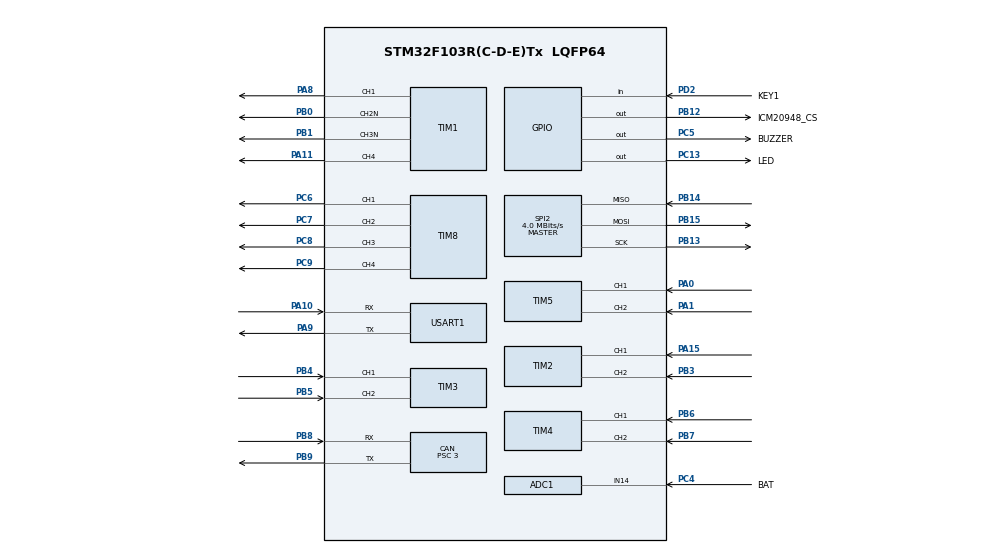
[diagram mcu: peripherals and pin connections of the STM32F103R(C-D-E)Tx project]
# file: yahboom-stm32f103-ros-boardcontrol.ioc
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ADC1.Channel-12\#ChannelRegularConversion=ADC_CHANNEL_14
ADC1.NbrOfConversionFlag=1
ADC1.Rank-12\#ChannelRegularConversion=1
ADC1.SamplingTime-12\#ChannelRegularConversion=ADC_SAMPLETIME_1CYCLE_5
ADC1.master=1
CAN.BS1=CAN_BS1_1TQ
CAN.BS2=CAN_BS2_1TQ
CAN.CalculateBaudRate=888888
CAN.CalculateTimeBit=1125
CAN.CalculateTimeQuantum=375.0
CAN.Prescaler=3
Dma.Request0=USART1_RX
Dma.Request1=USART1_TX
Dma.USART1_RX.0.Direction=DMA_PERIPH_TO_MEMORY
Dma.USART1_RX.0.Instance=DMA1_Channel5
Dma.USART1_RX.0.MemDataAlignment=DMA_MDATAALIGN_BYTE
Dma.USART1_RX.0.MemInc=DMA_MINC_ENABLE
Dma.USART1_RX.0.Mode=DMA_NORMAL
Dma.USART1_RX.0.PeriphDataAlignment=DMA_PDATAALIGN_BYTE
Dma.USART1_RX.0.PeriphInc=DMA_PINC_DISABLE
Dma.USART1_RX.0.Priority=DMA_PRIORITY_VERY_HIGH
Dma.USART1_TX.1.Direction=DMA_MEMORY_TO_PERIPH
Dma.USART1_TX.1.Instance=DMA1_Channel4
Dma.USART1_TX.1.MemDataAlignment=DMA_MDATAALIGN_BYTE
Dma.USART1_TX.1.MemInc=DMA_MINC_ENABLE
Dma.USART1_TX.1.Mode=DMA_NORMAL
Dma.USART1_TX.1.PeriphDataAlignment=DMA_PDATAALIGN_BYTE
Dma.USART1_TX.1.PeriphInc=DMA_PINC_DISABLE
Dma.USART1_TX.1.Priority=DMA_PRIORITY_VERY_HIGH
FREERTOS.Tasks01=AppController,40,128,AppControllerTask,As weak,NULL,Dynamic,NULL,NULL;AppEncoder,16,512,AppEncoderTask,As weak,NULL,Dynamic,NULL,NULL;AppIMU,24,512,AppIMUTask,As weak,NULL,Dynamic,NULL,NULL;AppManager,16,1048,AppManagerTask,As weak,NULL,Dynamic,NULL,NULL;AppHearthbeat,8,128,AppHearthbeatTask,As weak,NULL,Dynamic,NULL,NULL;AppMotion,16,512,AppMotionTask,As weak,NULL,Dynamic,NULL,NULL
FREERTOS.configTOTAL_HEAP_SIZE=16000
IWDG.Prescaler=IWDG_PRESCALER_64
Mcu.Family=STM32F1
Mcu.Name=STM32F103R(C-D-E)Tx
Mcu.Package=LQFP64
NVIC.DMA1_Channel4_IRQn=true\:5\:0\:false\:false\:true\:true\:false\:true\:true
NVIC.DMA1_Channel5_IRQn=true\:5\:0\:false\:false\:true\:true\:false\:true\:true
NVIC.PriorityGroup=NVIC_PRIORITYGROUP_4
NVIC.TIM7_IRQn=true\:15\:0\:false\:false\:true\:false\:false\:true\:true
NVIC.TimeBase=TIM7_IRQn
NVIC.TimeBaseIP=TIM7
NVIC.USART1_IRQn=true\:5\:0\:false\:false\:true\:true\:false\:true\:true
PA0-WKUP.Signal=S_TIM5_CH1
PA1.Signal=S_TIM5_CH2
PA10.Mode=Asynchronous
PA10.Signal=USART1_RX
PA11.Signal=S_TIM1_CH4
PA13.Mode=Serial_Wire
PA13.Signal=SYS_JTMS-SWDIO
PA14.Mode=Serial_Wire
PA14.Signal=SYS_JTCK-SWCLK
PA15.Signal=S_TIM2_CH1_ETR
PA8.Signal=S_TIM1_CH1
PA9.Mode=Asynchronous
PA9.Signal=USART1_TX
PB0.Mode=PWM Generation2 CH2N
PB0.Signal=TIM1_CH2N
PB1.Mode=PWM Generation3 CH3N
PB1.Signal=TIM1_CH3N
PB12.GPIO_Label=ICM20948_CS
PB12.Signal=GPIO_Output
PB13.Mode=Full_Duplex_Master
PB13.Signal=SPI2_SCK
PB14.Mode=Full_Duplex_Master
PB14.Signal=SPI2_MISO
PB15.Mode=Full_Duplex_Master
PB15.Signal=SPI2_MOSI
PB3.Signal=S_TIM2_CH2
PB4.Signal=S_TIM3_CH1
PB5.Signal=S_TIM3_CH2
PB6.Signal=S_TIM4_CH1
PB7.Signal=S_TIM4_CH2
PB8.Mode=CAN_Activate
PB8.Signal=CAN_RX
PB9.Mode=CAN_Activate
PB9.Signal=CAN_TX
PC13-TAMPER-RTC.GPIO_Label=LED
PC13-TAMPER-RTC.Signal=GPIO_Output
PC4.GPIO_Label=BAT
PC4.Signal=ADCx_IN14
PC5.GPIO_Label=BUZZER
PC5.Signal=GPIO_Output
PC6.Signal=S_TIM8_CH1
PC7.Signal=S_TIM8_CH2
PC8.Signal=S_TIM8_CH3
PC9.Signal=S_TIM8_CH4
PD0-OSC_IN.Mode=HSE-External-Oscillator
PD0-OSC_IN.Signal=RCC_OSC_IN
PD1-OSC_OUT.Mode=HSE-External-Oscillator
PD1-OSC_OUT.Signal=RCC_OSC_OUT
PD2.GPIO_Label=KEY1
PD2.GPIO_PuPd=GPIO_PULLUP
PD2.Signal=GPIO_Input
ProjectManager.HeapSize=0x200
ProjectManager.StackSize=0x400
ProjectManager.TargetToolchain=CMake
RCC.APB1Freq_Value=8000000
RCC.APB2Freq_Value=8000000
SH.ADCx_IN14.0=ADC1_IN14,IN14
SH.S_TIM1_CH1.0=TIM1_CH1,PWM Generation1 CH1
SH.S_TIM1_CH4.0=TIM1_CH4,PWM Generation4 CH4
SH.S_TIM2_CH1_ETR.0=TIM2_CH1,Encoder_Interface
SH.S_TIM2_CH2.0=TIM2_CH2,Encoder_Interface
SH.S_TIM3_CH1.0=TIM3_CH1,Encoder_Interface
SH.S_TIM3_CH2.0=TIM3_CH2,Encoder_Interface
SH.S_TIM4_CH1.0=TIM4_CH1,Encoder_Interface
SH.S_TIM4_CH2.0=TIM4_CH2,Encoder_Interface
SH.S_TIM5_CH1.0=TIM5_CH1,Encoder_Interface
SH.S_TIM5_CH2.0=TIM5_CH2,Encoder_Interface
SH.S_TIM8_CH1.0=TIM8_CH1,PWM Generation1 CH1
SH.S_TIM8_CH2.0=TIM8_CH2,PWM Generation2 CH2
SH.S_TIM8_CH3.0=TIM8_CH3,PWM Generation3 CH3
SH.S_TIM8_CH4.0=TIM8_CH4,PWM Generation4 CH4
SPI2.CalculateBaudRate=4.0 MBits/s
SPI2.Direction=SPI_DIRECTION_2LINES
SPI2.Mode=SPI_MODE_MASTER
SPI2.VirtualType=VM_MASTER
TIM1.Channel-PWM\ Generation1\ CH1=TIM_CHANNEL_1
TIM1.Channel-PWM\ Generation2\ CH2N=TIM_CHANNEL_2
TIM1.Channel-PWM\ Generation3\ CH3N=TIM_CHANNEL_3
TIM1.Channel-PWM\ Generation4\ CH4=TIM_CHANNEL_4
TIM2.EncoderMode=TIM_ENCODERMODE_TI12
TIM3.EncoderMode=TIM_ENCODERMODE_TI12
TIM4.EncoderMode=TIM_ENCODERMODE_TI12
TIM5.EncoderMode=TIM_ENCODERMODE_TI12
TIM8.Channel-PWM\ Generation1\ CH1=TIM_CHANNEL_1
TIM8.Channel-PWM\ Generation2\ CH2=TIM_CHANNEL_2
TIM8.Channel-PWM\ Generation3\ CH3=TIM_CHANNEL_3
TIM8.Channel-PWM\ Generation4\ CH4=TIM_CHANNEL_4
USART1.VirtualMode=VM_ASYNC
VP_ADC1_TempSens_Input.Mode=IN-TempSens
VP_FREERTOS_VS_CMSIS_V2.Mode=CMSIS_V2
VP_IWDG_VS_IWDG.Mode=IWDG_Activate
VP_SYS_VS_tim7.Mode=TIM7
VP_TIM1_VS_ClockSourceINT.Mode=Internal
VP_TIM8_VS_ClockSourceINT.Mode=Internal
board=custom

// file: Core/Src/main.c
/* USER CODE BEGIN Header */
/**
  ******************************************************************************
  * @file           : main.c
  * @brief          : Main program body
  ******************************************************************************
  * @attention
  *
  * Copyright (c) 2026 STMicroelectronics.
  * All rights reserved.
  *
  * This software is licensed under terms that can be found in the LICENSE file
  * in the root directory of this software component.
  * If no LICENSE file comes with this software, it is provided AS-IS.
  *
  ******************************************************************************
  */
/* USER CODE END Header */
#include "main.h"
#include "cmsis_os.h"
#include "adc.h"
#include "can.h"
#include "dma.h"
#include "iwdg.h"
#include "spi.h"
#include "tim.h"
#include "usart.h"
#include "gpio.h"

void SystemClock_Config(void);
void MX_FREERTOS_Init(void);

int main(void)
{

  /* MCU Configuration--------------------------------------------------------*/

  /* Reset of all peripherals, Initializes the Flash interface and the Systick. */
  HAL_Init();

  /* Configure the system clock */
  SystemClock_Config();

  /* Initialize all configured peripherals */
  MX_GPIO_Init();
  MX_DMA_Init();
  MX_IWDG_Init();
  MX_SPI2_Init();
  MX_TIM1_Init();
  MX_TIM2_Init();
  MX_TIM3_Init();
  MX_TIM4_Init();
  MX_TIM5_Init();
  MX_TIM8_Init();
  MX_USART1_UART_Init();
  MX_ADC1_Init();
  MX_CAN_Init();

  /* Init scheduler */
  osKernelInitialize();  /* Call init function for freertos objects (in cmsis_os2.c) */
  MX_FREERTOS_Init();

  /* Start scheduler */
  osKernelStart();

  /* We should never get here as control is now taken by the scheduler */

  /* Infinite loop */
  while (1)
  {

  }
}

void SystemClock_Config(void)
{
  RCC_OscInitTypeDef RCC_OscInitStruct = {0};
  RCC_ClkInitTypeDef RCC_ClkInitStruct = {0};
  RCC_PeriphCLKInitTypeDef PeriphClkInit = {0};

  /** Initializes the RCC Oscillators according to the specified parameters
  * in the RCC_OscInitTypeDef structure.
  */
  RCC_OscInitStruct.OscillatorType = RCC_OSCILLATORTYPE_HSI|RCC_OSCILLATORTYPE_LSI;
  RCC_OscInitStruct.HSIState = RCC_HSI_ON;
  RCC_OscInitStruct.HSICalibrationValue = RCC_HSICALIBRATION_DEFAULT;
  RCC_OscInitStruct.LSIState = RCC_LSI_ON;
  RCC_OscInitStruct.PLL.PLLState = RCC_PLL_NONE;
  if (HAL_RCC_OscConfig(&RCC_OscInitStruct) != HAL_OK)
  {
    Error_Handler();
  }

  /** Initializes the CPU, AHB and APB buses clocks
  */
  RCC_ClkInitStruct.ClockType = RCC_CLOCKTYPE_HCLK|RCC_CLOCKTYPE_SYSCLK
                              |RCC_CLOCKTYPE_PCLK1|RCC_CLOCKTYPE_PCLK2;
  RCC_ClkInitStruct.SYSCLKSource = RCC_SYSCLKSOURCE_HSI;
  RCC_ClkInitStruct.AHBCLKDivider = RCC_SYSCLK_DIV1;
  RCC_ClkInitStruct.APB1CLKDivider = RCC_HCLK_DIV1;
  RCC_ClkInitStruct.APB2CLKDivider = RCC_HCLK_DIV1;

  if (HAL_RCC_ClockConfig(&RCC_ClkInitStruct, FLASH_LATENCY_0) != HAL_OK)
  {
    Error_Handler();
  }
  PeriphClkInit.PeriphClockSelection = RCC_PERIPHCLK_ADC;
  PeriphClkInit.AdcClockSelection = RCC_ADCPCLK2_DIV2;
  if (HAL_RCCEx_PeriphCLKConfig(&PeriphClkInit) != HAL_OK)
  {
    Error_Handler();
  }
}

/* USER CODE BEGIN 4 */
// System call stubs for Newlib to use printf to output to the UART1
int _write(int file, char *ptr, int len) {
  HAL_UART_Transmit(&huart1, (uint8_t *)ptr, len, HAL_MAX_DELAY);
  return len;
}
/* USER CODE END 4 */

void HAL_TIM_PeriodElapsedCallback(TIM_HandleTypeDef *htim)
{
  if (htim->Instance == TIM7)
  {
    HAL_IncTick();
  }
}

void Error_Handler(void)
{
  __disable_irq();
  while (1)
  {
  }
}

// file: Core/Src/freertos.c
/* USER CODE BEGIN Header */
/**
  ******************************************************************************
  * File Name          : freertos.c
  * Description        : Code for freertos applications
  ******************************************************************************
  * @attention
  *
  * Copyright (c) 2026 STMicroelectronics.
  * All rights reserved.
  *
  * This software is licensed under terms that can be found in the LICENSE file
  * in the root directory of this software component.
  * If no LICENSE file comes with this software, it is provided AS-IS.
  *
  ******************************************************************************
  */
/* USER CODE END Header */

#include "FreeRTOS.h"
#include "task.h"
#include "main.h"
#include "cmsis_os.h"

/* USER CODE BEGIN Includes */
#include "global.h"
/* USER CODE END Includes */

/* Definitions for AppController */
osThreadId_t AppControllerHandle;
const osThreadAttr_t AppController_attributes = {
  .name = "AppController",
  .stack_size = 512 * 4,
  .priority = (osPriority_t) osPriorityHigh,
};
/* Definitions for AppEncoder */
osThreadId_t AppEncoderHandle;
const osThreadAttr_t AppEncoder_attributes = {
  .name = "AppEncoder",
  .stack_size = 512 * 4,
  .priority = (osPriority_t) osPriorityBelowNormal,
};
/* Definitions for AppIMU */
osThreadId_t AppIMUHandle;
const osThreadAttr_t AppIMU_attributes = {
  .name = "AppIMU",
  .stack_size = 512 * 4,
  .priority = (osPriority_t) osPriorityNormal,
};
/* Definitions for AppManager */
osThreadId_t AppManagerHandle;
const osThreadAttr_t AppManager_attributes = {
  .name = "AppManager",
  .stack_size = 1048 * 4,
  .priority = (osPriority_t) osPriorityBelowNormal,
};
/* Definitions for AppHearthbeat */
osThreadId_t AppHearthbeatHandle;
const osThreadAttr_t AppHearthbeat_attributes = {
  .name = "AppHearthbeat",
  .stack_size = 512 * 4,
  .priority = (osPriority_t) osPriorityLow,
};
/* Definitions for AppMotion */
osThreadId_t AppMotionHandle;
const osThreadAttr_t AppMotion_attributes = {
  .name = "AppMotion",
  .stack_size = 512 * 4,
  .priority = (osPriority_t) osPriorityBelowNormal,
};

void AppControllerTask(void *argument);
void AppEncoderTask(void *argument);
void AppIMUTask(void *argument);
void AppManagerTask(void *argument);
void AppHearthbeatTask(void *argument);
void AppMotionTask(void *argument);

void MX_FREERTOS_Init(void); /* (MISRA C 2004 rule 8.1) */

void MX_FREERTOS_Init(void) {

  /* USER CODE BEGIN RTOS_QUEUES */
  /* add queues, ... */
  system_msg_queue = osMessageQueueNew(10, sizeof(system_msg_t), NULL);
  /* USER CODE END RTOS_QUEUES */

  /* Create the thread(s) */
  /* creation of AppController */
  AppControllerHandle = osThreadNew(AppControllerTask, NULL, &AppController_attributes);

  /* creation of AppEncoder */
  AppEncoderHandle = osThreadNew(AppEncoderTask, NULL, &AppEncoder_attributes);

  /* creation of AppIMU */
  AppIMUHandle = osThreadNew(AppIMUTask, NULL, &AppIMU_attributes);

  /* creation of AppManager */
  AppManagerHandle = osThreadNew(AppManagerTask, NULL, &AppManager_attributes);

  /* creation of AppHearthbeat */
  AppHearthbeatHandle = osThreadNew(AppHearthbeatTask, NULL, &AppHearthbeat_attributes);

  /* creation of AppMotion */
  AppMotionHandle = osThreadNew(AppMotionTask, NULL, &AppMotion_attributes);

}

__weak void AppControllerTask(void *argument)
{
  for(;;)
  {
    osDelay(1);
  }
}

__weak void AppEncoderTask(void *argument)
{
  for(;;)
  {
    osDelay(1);
  }
}

__weak void AppIMUTask(void *argument)
{
  for(;;)
  {
    osDelay(1);
  }
}

__weak void AppManagerTask(void *argument)
{
  for(;;)
  {
    osDelay(1);
  }
}

__weak void AppHearthbeatTask(void *argument)
{
  for(;;)
  {
    osDelay(1);
  }
}

__weak void AppMotionTask(void *argument)
{
  for(;;)
  {
    osDelay(1);
  }
}
